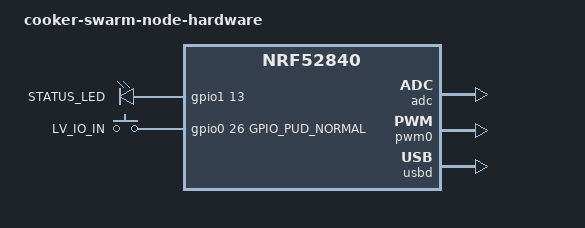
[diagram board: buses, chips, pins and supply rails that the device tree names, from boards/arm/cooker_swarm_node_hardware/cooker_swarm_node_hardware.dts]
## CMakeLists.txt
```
cmake_minimum_required(VERSION 3.8.2)

#set(BOARD_ROOT ${CMAKE_CURRENT_LIST_DIR})
#set(BOARD cooker_swarm_node_hardware)

include($ENV{ZEPHYR_BASE}/cmake/app/boilerplate.cmake NO_POLICY_SCOPE)
project(cooker-node)

target_sources(app PRIVATE
  src/main.c
  src/cooker.c
  src/cos.c
  src/cts.c
  src/ess.c
  src/remote_temp.c
  src/pid.c
)
```

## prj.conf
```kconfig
# POWER SAVING
#CONFIG_DEBUG=n
#CONFIG_SERIAL=n
#CONFIG_UART_NRFX=n
#CONFIG_SPEED_OPTIMIZATIONS=y
#CONFIG_BT_DEBUG_LOG=n

CONFIG_LOG=y
#CONFIG_LOG_BACKEND_UART=n

CONFIG_BT_MAX_CONN=2
CONFIG_BT_MAX_SCO_CONN=2

#CONFIG_CONSOLE=n
#CONFIG_UART_CONSOLE=n

# GENERAL
CONFIG_REBOOT=y

# DEVICES
CONFIG_ADC=y
CONFIG_GPIO=y
CONFIG_PWM=y

# BLUETOOTH
CONFIG_BT=y
CONFIG_BT_CENTRAL=y
CONFIG_BT_PERIPHERAL=y
CONFIG_BT_GATT_CLIENT=y
CONFIG_BT_DEVICE_NAME="cooker-swarm-node"
CONFIG_BT_CTLR_TX_PWR_PLUS_8=y

# POWER MANAGEMENT
CONFIG_SYS_POWER_MANAGEMENT=y
CONFIG_DEVICE_POWER_MANAGEMENT=y
```

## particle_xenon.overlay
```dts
/ {
	leds {
		compatible = "gpio-leds";
		led0: led_0 {
		  gpios = <&gpio1 13 0>;
		  label = "STATUS_LED";
	  	};
	};

	gpio_keys {
		compatible = "gpio-keys";
		lv_io_in: button_0 {
			gpios = <&gpio0 26 GPIO_PUD_NORMAL>;
			label = "LV_IO_IN";
		};
	};

	/* These aliases are provided for compatibility with samples */
	aliases {
		led0 = &led0;
	};
};

&pwm0 {
	status = "okay";
	ch0-pin = <45>;	// status LED
	ch0-inverted;
	ch1-pin = <8>;	// power out
	ch1-inverted;
};
```

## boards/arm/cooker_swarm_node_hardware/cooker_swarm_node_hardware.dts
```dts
/*
 * Copyright (c) 2020 Christian Hirsch
 *
 * SPDX-License-Identifier: Apache-2.0
 */

/dts-v1/;
#include <nordic/nrf52840_qiaa.dtsi>

/ {
	model = "cooker-swarm-node-hardware";
	compatible = "nordic,nrf52840-qiaa",
			   "nordic,nrf52840";

	chosen {
		zephyr,sram = &sram0;
		zephyr,flash = &flash0;
		zephyr,code-partition = &slot0_partition;
	};

	leds {
		compatible = "gpio-leds";
		led0: led_0 {
		  gpios = <&gpio1 13 0>;
		  label = "STATUS_LED";
	  	};
	};

	gpio_keys {
		compatible = "gpio-keys";
		lv_io_in: button_0 {
			gpios = <&gpio0 26 GPIO_PUD_NORMAL>;
			label = "LV_IO_IN";
		};
	};

	/* These aliases are provided for compatibility with samples */
	aliases {
		led0 = &led0;
	};
};

&adc {
	status = "okay";
};

&gpiote {
	status = "okay";
};

&gpio0 {
	status = "okay";
};

&gpio1 {
	status = "okay";
};

&pwm0 {
	status = "okay";
	ch0-pin = <45>;	// status LED
	ch0-inverted;
	ch1-pin = <8>;	// power out
	ch1-inverted;
};

&flash0 {
	/*
	 * For more information, see:
	 * http://docs.zephyrproject.org/latest/guides/dts/index.html#flash-partitions
	 */
	partitions {
		compatible = "fixed-partitions";
		#address-cells = <1>;
		#size-cells = <1>;

		boot_partition: partition@0 {
			label = "mcuboot";
			reg = <0x000000000 0x0000C000>;
		};
		slot0_partition: partition@c000 {
			label = "image-0";
			reg = <0x0000C000 0x000067000>;
		};
		slot1_partition: partition@73000 {
			label = "image-1";
			reg = <0x00073000 0x000067000>;
		};
		scratch_partition: partition@da000 {
			label = "image-scratch";
			reg = <0x000da000 0x0001e000>;
		};

		/*
		 * The flash starting at 0x000f8000 and ending at
		 * 0x000fffff is reserved for use by the application.
		 */

		/* Storage partition will be used by FCB/NFFS/NVS if enabled. */
		storage_partition: partition@f8000 {
			label = "storage";
			reg = <0x000f8000 0x00008000>;
		};
	};
};

&usbd {
	compatible = "nordic,nrf-usbd";
	status = "okay";
};
```

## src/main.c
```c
/*
 *
 */

#include <zephyr.h>
#include <zephyr/types.h>
#include <misc/byteorder.h>
#include <logging/log.h>
#include <settings/settings.h>
#include <device.h>
#include <gpio.h>
#include <soc.h>

#include <stddef.h>
#include <string.h>
#include <errno.h>

#include <bluetooth/bluetooth.h>
#include <bluetooth/hci.h>
#include <bluetooth/conn.h>
#include <bluetooth/uuid.h>
#include <bluetooth/gatt.h>

#include "cooker.h"
#include "remote_temp.h"
#include "cos.h"
#include "cts.h"

#include "config.h"

#include <drivers/pwm.h>


#ifndef IBEACON_RSSI
#define IBEACON_RSSI 0xc8
#endif

#define SENSE_INTERVAL 5
#define MEASUREMENTS_SIZE  10

/* in microseconds */
#define MIN_PERIOD	(USEC_PER_SEC / 64U)

/* in microseconds */
#define MAX_PERIOD	USEC_PER_SEC

// BT_GAP_ADV_SLOW_INT_MIN = 0x0640 ^= 1s
// BT_GAP_ADV_SLOW_INT_MAX = 0x0780 ^= 1.2s
#define BT_LE_ADV_CONN_NAME_ID BT_LE_ADV_PARAM(BT_LE_ADV_OPT_CONNECTABLE | \
                         BT_LE_ADV_OPT_USE_NAME | BT_LE_ADV_OPT_USE_IDENTITY, \
                         BT_GAP_ADV_SLOW_INT_MIN, \
                         BT_GAP_ADV_SLOW_INT_MAX)

LOG_MODULE_REGISTER(main);

void create_device_list(void);

struct {
	u32_t timestamp;
	u16_t battery;
} measurements[MEASUREMENTS_SIZE];

s16_t buf_start = 0;
s16_t buf_end   = 0;
u32_t sense_interval_mult = 1;

struct bt_le_adv_param *adv_params = BT_LE_ADV_CONN_NAME_ID;

static const struct bt_data ad[] = {
		BT_DATA_BYTES(BT_DATA_FLAGS, BT_LE_AD_NO_BREDR),
		BT_DATA_BYTES(BT_DATA_UUID16_ALL, 0xaa, 0xfe),
		BT_DATA_BYTES(BT_DATA_SVC_DATA16,
				0xaa, 0xfe,		/* Eddystone UUID */
				0x10,			/* Eddystone-URL frame type */
				0x04,			/* Calibrated Tx power at 0m */
				0x02,			/* URL Scheme Prefix http:// */
				'b','r','e','w','c','e','.',
				'c','h','r','i','v','i','e','h',
				0x03)
};

static void connected(struct bt_conn *conn, u8_t err)
{
	if (err) {
		LOG_INF("Connection failed (err %u)\n", err);
		return;
	}

	struct bt_conn_info info;
	if(bt_conn_get_info(conn, &info) != 0) {
		return;
	}
	if(info.role == BT_CONN_ROLE_MASTER) {
		LOG_INF("BT_CONN_ROLE_MASTER");
		return;
	}

	bt_le_adv_stop();
	LOG_INF("Connected with role %u", info.role);
}

static void disconnected(struct bt_conn *conn, u8_t reason)
{
	struct bt_conn_info info;
	if(bt_conn_get_info(conn, &info) != 0) {
		return;
	}
	if(info.role == BT_CONN_ROLE_MASTER) {
		return;
	}

	LOG_INF("Disconnected (reason %u)", reason);

	int err = 0;
	err = bt_le_adv_start(adv_params, ad, ARRAY_SIZE(ad), NULL, 0);
	if (err) {
		LOG_ERR("Advertising failed to start (err %d)", err);
		return;
	}
    LOG_INF("Advertising successfully started");
}

static struct bt_conn_cb conn_callbacks = {
	.connected = connected,
	.disconnected = disconnected,
};

static void bt_ready(int err)
{
	if (err) {
		return;
	}

	if (IS_ENABLED(CONFIG_SETTINGS)) {
		settings_load();
	}

	err = bt_le_adv_start(adv_params, ad, ARRAY_SIZE(ad), NULL, 0);
	if (err) {
		LOG_ERR("Advertising failed to start (err %d)", err);
		return;
	}
}

void main(void)
{
	LOG_INF("Application started");
	int err = 0;

	err = bt_enable(bt_ready);
	if (err) {
		LOG_ERR("Bluetooth init failed (err %d)", err);
		//return;
	}
    bt_conn_cb_register(&conn_callbacks);

    initilize_remote();
	cooker_init();

	while (1) {
		k_sleep(K_FOREVER);
	}
}
```

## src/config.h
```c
#if defined(DT_ALIAS_PWM_0_LABEL)
#define PWM_DRIVER	DT_ALIAS_PWM_0_LABEL

#if defined(DT_ALIAS_PWM_0_CH0_PIN)
#define STATUS_LED_CHANNEL	DT_ALIAS_PWM_0_CH0_PIN
#else
#error "Choose status LED PWM channel"
#endif

#if defined(DT_ALIAS_PWM_0_CH1_PIN)
#define POWER_OUT_CHANNEL	DT_ALIAS_PWM_0_CH1_PIN
#else
#error "Choose power out PWM channel"
#endif

#else
#error "Choose supported PWM driver"
#endif

#ifdef CONFIG_SOC_NRF52840_QIAA
#ifdef DT_ALIAS_ADC_0_LABEL
#include <hal/nrf_saadc.h>
#define ADC_DRIVER DT_ALIAS_ADC_0_LABEL
#define BATTERY_SENSE_PIN NRF_SAADC_INPUT_AIN2  // P0.04/AIN2
#else
#error "you need to define ADC 0"
#endif
#endif

#ifndef DT_GPIO_KEYS_BUTTON_0_GPIOS_CONTROLLER
#ifdef BUTTON0_GPIO_NAME
#define DT_ALIAS_SW0_GPIOS_CONTROLLER SW0_GPIO_NAME
#else
#error BUTTON0_GPIO_NAME or DT_GPIO_KEYS_BUTTON_0_GPIOS_CONTROLLER needs to be set in board.h
#endif
#endif
#define GPIO_DRIVER	DT_GPIO_KEYS_BUTTON_0_GPIOS_CONTROLLER

#ifdef DT_GPIO_KEYS_BUTTON_0_GPIOS_PIN
#define IO_INPUT_PIN     DT_GPIO_KEYS_BUTTON_0_GPIOS_PIN
#else
#error DT_GPIO_KEYS_BUTTON_0_GPIOS_CONTROLLER needs to be set in board.h
#endif

#ifdef DT_GPIO_KEYS_BUTTON_0_GPIOS_FLAGS
#define IO_INPUT_PIN_EDGE    (DT_GPIO_KEYS_BUTTON_0_GPIOS_FLAGS | GPIO_INT_EDGE | GPIO_INT_ACTIVE_HIGH)
#else
#error DT_GPIO_KEYS_BUTTON_0_GPIOS_FLAGS needs to be set in board.h
#endif

#ifdef DT_ALIAS_GPIO_0_LABEL
#define IO_OUTPUT_PORT	DT_ALIAS_GPIO_0_LABEL
#define IO_OUTPUT_PIN	6	// P0.06
#else
#error "Choose supported GPIO 0 driver"
#endif
```

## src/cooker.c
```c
#include "cooker.h"

#include <zephyr.h>
#include <kernel.h>
#include <logging/log.h>
#include <device.h>

#include <adc.h>
#include <drivers/gpio.h>
#include <drivers/pwm.h>

#include "config.h"
#include "cos.h"
#include "pid.h"
#include "remote_temp.h"

#define	PERIOD	1000000UL	// 1000000ns = 1 kHz

u8_t output_power_level = 0;
u8_t output_io_level = 0;

s16_t input_power_level = 0;

static struct pid_state control_loop_pid;

struct device *adc_dev;
struct device *gpio_dev;
struct device *pwm_dev;

K_SEM_DEFINE(manual_enter_sem, 1, 1);
K_SEM_DEFINE(is_in_on_loop, 1, 1);

K_MUTEX_DEFINE(cooker_control_mutex);

static struct gpio_callback gpio_cb;

#define STACK_SIZE 1024
#define PRIORITY 5

K_THREAD_STACK_DEFINE(manual_power_loop_stack, STACK_SIZE);
struct k_thread manual_power_loop_data;
k_tid_t manual_power_loop_tid;

K_THREAD_STACK_DEFINE(is_on_loop_stack, STACK_SIZE);
struct k_thread is_on_loop_data;
k_tid_t is_on_loop_tid;

K_THREAD_STACK_DEFINE(cooker_control_loop_stack, STACK_SIZE);
struct k_thread cooker_control_loop_data;
k_tid_t cooker_control_loop_tid;

static void cooker_control_loop(struct k_timer *timer);
K_TIMER_DEFINE(cooker_control_loop_timer, cooker_control_loop, NULL);

static const struct adc_channel_cfg adc_cfg = {
		.gain             = ADC_GAIN_1_6,
		.reference        = ADC_REF_VDD_1_4,
		.acquisition_time = ADC_ACQ_TIME(ADC_ACQ_TIME_MICROSECONDS, 40),
		.channel_id       = 0,
		.input_positive   = BATTERY_SENSE_PIN,
};

struct adc_sequence adc_sequence = {
		.buffer      = &input_power_level,
		.buffer_size = sizeof(input_power_level),
		.resolution  = 10,
};

void set_status_led_level(u8_t level);

LOG_MODULE_REGISTER(cooker);

void manual_power_loop()
{
	k_sleep(100);	// debounce

	if(k_mutex_lock(&cooker_control_mutex, K_FOREVER) != 0)
	{
		k_sem_give(&manual_enter_sem);
		return;
	}

	while(get_input_io_level()) {

		set_output_io_level(1);

		u8_t power = get_input_power_level();
		set_output_power_level(power);

		k_sleep(20);
	}
	set_output_io_level(0);

	k_mutex_unlock(&cooker_control_mutex);

	k_sem_give(&manual_enter_sem);
}

void is_on_loop()
{
	while (get_output_io_level())
	{
		set_status_led_level(0xff);
		k_sleep(10);
		set_status_led_level(0x00);
		k_sleep(200);
		set_status_led_level(0xff);
		k_sleep(10);
		set_status_led_level(0x00);
		k_sleep(1750);
	}

	k_sem_give(&is_in_on_loop);
}

void cooker_control_loop_worker()
{
	if(k_mutex_lock(&cooker_control_mutex, K_NO_WAIT) != 0) {
		cooker_stop_control_loop();
		return;
	}

	s32_t value  = (s32_t) remote_read_temp();
	if (value < -27315) {
		LOG_ERR("Error getting remote temperature");
		set_output_io_level(0);
		k_mutex_unlock(&cooker_control_mutex);
		return;
	}
	LOG_INF("Setpoint = %d ; value = %d", control_loop_pid.setpoint, value);
	s32_t output = pid_calc_control_effort(&control_loop_pid, value) / 100;
	const s32_t cutoff = (255 * 500) / 3500;

	LOG_INF("Set output level %i (int_error = %i)", (output * 3500) / 255,
			control_loop_pid.int_error);
	if (output < cutoff) {
		if (get_output_io_level() != 0) {
			set_output_io_level(0);
		}
		cooker_start_control_loop(K_SECONDS(2));
		k_mutex_unlock(&cooker_control_mutex);
		return;
	}

	if (get_output_io_level() != 1) {
		set_output_io_level(1);
	}
	output -= cutoff;
	output *= 255;
	output /= 255 - cutoff;
	set_output_power_level((u8_t)output);

	cooker_start_control_loop(K_SECONDS(2));
	k_mutex_unlock(&cooker_control_mutex);
}

void io_switched(struct device *gpiob, struct gpio_callback *cb,
		u32_t pins)
{
	if(k_sem_take(&manual_enter_sem, K_NO_WAIT) == 0)
	{
		k_thread_create(&manual_power_loop_data, manual_power_loop_stack,
				K_THREAD_STACK_SIZEOF(manual_power_loop_stack),
				manual_power_loop,
				NULL, NULL, NULL,
				PRIORITY + 1, 0, K_NO_WAIT);
	}
}

static void cooker_control_loop(struct k_timer *timer)
{
	k_thread_create(&cooker_control_loop_data, cooker_control_loop_stack,
			K_THREAD_STACK_SIZEOF(cooker_control_loop_stack),
			cooker_control_loop_worker,
			NULL, NULL, NULL,
			PRIORITY + 1, 0, K_NO_WAIT);
}

void cooker_init()
{
	k_sem_init(&manual_enter_sem, 1, 1);

	pid_initialize_state(&control_loop_pid);
	control_loop_pid.setpoint = 2750;
	control_loop_pid.p = 100;
	control_loop_pid.i =   1;
	control_loop_pid.int_error_max = 25500;
	control_loop_pid.output_max = 25500;
	control_loop_pid.output_min = 0;

	adc_dev = device_get_binding(ADC_DRIVER);
	if (!adc_dev) {
		LOG_ERR("Cannot find %s!\n", ADC_DRIVER);
		return;
	}

	gpio_dev = device_get_binding(GPIO_DRIVER);
	if(!gpio_dev) {
		LOG_ERR("Cannot find %s!\n", GPIO_DRIVER);
		return;
	}

	pwm_dev = device_get_binding(PWM_DRIVER);
	if (!pwm_dev) {
		LOG_ERR("Cannot find %s!\n", PWM_DRIVER);
		return;
	}

	adc_channel_setup(adc_dev, &adc_cfg);

	gpio_pin_configure(gpio_dev, IO_INPUT_PIN,
			GPIO_DIR_IN | GPIO_INT | GPIO_INT_DEBOUNCE | IO_INPUT_PIN_EDGE);

	gpio_init_callback(&gpio_cb, io_switched, BIT(IO_INPUT_PIN));

	gpio_add_callback(gpio_dev, &gpio_cb);
	gpio_pin_enable_callback(gpio_dev, IO_INPUT_PIN);

	gpio_pin_configure(gpio_dev, IO_OUTPUT_PIN, GPIO_DIR_OUT);
	gpio_pin_write(gpio_dev, IO_OUTPUT_PIN, 0);
}

void cooker_start_control_loop(s32_t duration) {
	k_timer_start(&cooker_control_loop_timer, duration, 0);
}

void cooker_stop_control_loop(void) {
	k_timer_stop(&cooker_control_loop_timer);
}

/* 0xa8 (min) to 0x00 (max) */
u8_t get_input_power_level()
{
	int ret = 0;

	if(adc_channel_setup(adc_dev, &adc_cfg) != 0)
		return 255;

	adc_sequence.channels = BIT(adc_cfg.channel_id);
	ret = adc_read(adc_dev, &adc_sequence);

	if(ret < 0)
		return 255;

	input_power_level = (input_power_level >> 2) & 0x00ff;
	if (input_power_level > 0xf0UL)
		input_power_level = 0;
	input_power_level *= 0xffUL;
	input_power_level /= 0xaaUL;
	input_power_level  = 255 - input_power_level;

	cos_input_power_notify((u8_t) input_power_level);
	return (u8_t) input_power_level;
}

/*
 * VDD = low power
 * GND = full power
 */
void set_output_power_level(u8_t level)
{
	LOG_INF("Set output power level to %u", level);
	return;
	output_power_level = level;

	if (get_output_io_level() == 0)
		output_power_level = 0;

	cos_output_power_notify(output_power_level);

	u32_t period = (u32_t) output_power_level * PERIOD / 255UL;

	if (pwm_pin_set_nsec(pwm_dev, POWER_OUT_CHANNEL,
			PERIOD, period)) {
		LOG_ERR("pwm pin set fails\n");
		return;
	}
}

u8_t get_output_power_level()
{
	return output_power_level;
}

u8_t get_input_io_level()
{
	u32_t value;
	gpio_pin_read(gpio_dev, IO_INPUT_PIN, &value);
	cos_input_io_notify((u8_t) (value > 0));
	return (u8_t) (value > 0) ;
}

void set_output_io_level(u8_t level)
{
	LOG_INF("Set output io level to %u", level);
	return;
	output_io_level = level;
	cos_output_io_notify(output_io_level);
	if(output_io_level)
	{
		gpio_pin_write(gpio_dev, IO_OUTPUT_PIN, 1);

		if(k_sem_take(&is_in_on_loop, K_NO_WAIT) == 0)
		{
			k_thread_create(&is_on_loop_data, is_on_loop_stack,
					K_THREAD_STACK_SIZEOF(is_on_loop_stack),
					is_on_loop,
					NULL, NULL, NULL,
					7, 0, K_NO_WAIT);
		}
	}
	else
	{
		set_output_power_level(0);
		gpio_pin_write(gpio_dev, IO_OUTPUT_PIN, 0);
	}
}

u8_t get_output_io_level()
{
	return output_io_level;
}

void set_status_led_level(u8_t level)
{
	u32_t period = (u32_t) level * PERIOD / 255UL;

	if (pwm_pin_set_nsec(pwm_dev, STATUS_LED_CHANNEL,
			PERIOD, period)) {
		LOG_ERR("pwm pin set fails\n");
	}
}

void cooker_set_control_setpoint(s32_t setpoint)
{
	control_loop_pid.setpoint = setpoint;
}

void cooker_set_control_pid_p_value(s32_t p)
{
	control_loop_pid.p = p;
}

void cooker_set_control_pid_i_value(s32_t i)
{
	control_loop_pid.i = i;
}

void cooker_set_control_pid_d_value(s32_t d)
{
	control_loop_pid.d = d;
}
```

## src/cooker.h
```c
#include <zephyr/types.h>

#ifdef __cplusplus
extern "C" {
#endif

void cooker_init();

u8_t get_input_power_level();

void set_output_power_level(u8_t level);
u8_t get_output_power_level();

u8_t get_input_io_level();

void set_output_io_level(u8_t level);
u8_t get_output_io_level();

void cooker_start_control_loop(s32_t duration);
void cooker_stop_control_loop(void);

void cooker_set_control_setpoint(s32_t setpoint);
void cooker_set_control_pid_p_value(s32_t p);
void cooker_set_control_pid_i_value(s32_t i);
void cooker_set_control_pid_d_value(s32_t d);

#ifdef __cplusplus
}
#endif
```

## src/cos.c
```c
#include <zephyr.h>
#include <kernel.h>
#include <zephyr/types.h>
#include <stddef.h>
#include <string.h>
#include <errno.h>
#include <misc/byteorder.h>

#include <bluetooth/bluetooth.h>
#include <bluetooth/addr.h>
#include <bluetooth/hci.h>
#include <bluetooth/conn.h>
#include <bluetooth/uuid.h>
#include <bluetooth/gatt.h>

#include "cooker.h"
#include "remote_temp.h"
#include "uuid.h"

#include "cos.h"

u8_t input_io_notify_enabled = 0;
u8_t input_power_notify_enabled = 0;

u8_t output_io_notify_enabled = 0;
u8_t output_power_notify_enabled = 0;

bt_addr_le_t remote_temp_device;
u16_t remote_temp_handle;

extern struct k_mutex cooker_control_mutex;

static void cos_set_input_io_ccc_cfg(const struct bt_gatt_attr *attr,
				 u16_t value);
static ssize_t cos_get_input_io_level(struct bt_conn *conn, const struct bt_gatt_attr *attr,
			 void *buf, u16_t len, u16_t offset);

static void cos_set_input_power_ccc_cfg(const struct bt_gatt_attr *attr,
				 u16_t value);
static ssize_t cos_get_input_power_level(struct bt_conn *conn, const struct bt_gatt_attr *attr,
			 void *buf, u16_t len, u16_t offset);

static void cos_set_output_io_ccc_cfg(const struct bt_gatt_attr *attr,
				 u16_t value);
static ssize_t cos_set_output_io_level(struct bt_conn *conn, const struct bt_gatt_attr *attr,
                        const void *buf, u16_t len, u16_t offset,
                        u8_t flags);

static void cos_set_output_power_ccc_cfg(const struct bt_gatt_attr *attr,
				 u16_t value);
static ssize_t cos_set_output_power_level(struct bt_conn *conn, const struct bt_gatt_attr *attr,
                        const void *buf, u16_t len, u16_t offset,
                        u8_t flags);

static ssize_t cos_set_remote_temp_probe(struct bt_conn *conn, const struct bt_gatt_attr *attr,
                        const void *buf, u16_t len, u16_t offset,
                        u8_t flags);

static ssize_t cos_set_control_state(struct bt_conn *conn, const struct bt_gatt_attr *attr,
                        const void *buf, u16_t len, u16_t offset,
                        u8_t flags);

static ssize_t cos_set_control_setpoint(struct bt_conn *conn, const struct bt_gatt_attr *attr,
                        const void *buf, u16_t len, u16_t offset,
                        u8_t flags);

static ssize_t cos_set_control_pid(struct bt_conn *conn, const struct bt_gatt_attr *attr,
                        const void *buf, u16_t len, u16_t offset,
                        u8_t flags);

/* Battery Service Declaration */
BT_GATT_SERVICE_DEFINE(cooker_service_cvs,
	BT_GATT_PRIMARY_SERVICE(BT_UUID_COS),

	BT_GATT_CHARACTERISTIC(BT_UUID_COS_INPUT_IO,
			       BT_GATT_CHRC_READ | BT_GATT_CHRC_NOTIFY,
			       BT_GATT_PERM_READ, cos_get_input_io_level, NULL, NULL),
	BT_GATT_CCC(cos_set_input_io_ccc_cfg, BT_GATT_PERM_READ | BT_GATT_PERM_WRITE),
	
	BT_GATT_CHARACTERISTIC(BT_UUID_COS_INPUT_POWER,
			       BT_GATT_CHRC_READ | BT_GATT_CHRC_NOTIFY,
			       BT_GATT_PERM_READ, cos_get_input_power_level, NULL, NULL),
	BT_GATT_CCC(cos_set_input_power_ccc_cfg, BT_GATT_PERM_READ | BT_GATT_PERM_WRITE),
	
	BT_GATT_CHARACTERISTIC(BT_UUID_COS_OUTPUT_IO,
			       BT_GATT_CHRC_WRITE | BT_GATT_CHRC_NOTIFY,
			       BT_GATT_PERM_WRITE, NULL, cos_set_output_io_level, NULL),
	BT_GATT_CCC(cos_set_output_io_ccc_cfg, BT_GATT_PERM_READ | BT_GATT_PERM_WRITE),
	
	BT_GATT_CHARACTERISTIC(BT_UUID_COS_OUTPUT_POWER,
			       BT_GATT_CHRC_WRITE | BT_GATT_CHRC_NOTIFY,
			       BT_GATT_PERM_WRITE, NULL, cos_set_output_power_level, NULL),
	BT_GATT_CCC(cos_set_output_power_ccc_cfg, BT_GATT_PERM_READ | BT_GATT_PERM_WRITE),

	BT_GATT_CHARACTERISTIC(BT_UUID_COS_REMOTE_TEMP_PROBE,
				BT_GATT_CHRC_WRITE,
				BT_GATT_PERM_WRITE, NULL, cos_set_remote_temp_probe, NULL),
	BT_GATT_CCC(NULL, BT_GATT_PERM_NONE),

	BT_GATT_CHARACTERISTIC(BT_UUID_COS_CONTROL_STATE,
				BT_GATT_CHRC_WRITE,
				BT_GATT_PERM_WRITE, NULL, cos_set_control_state, NULL),
	BT_GATT_CCC(NULL, BT_GATT_PERM_NONE),

	BT_GATT_CHARACTERISTIC(BT_UUID_COS_CONTROL_SETPOINT,
			BT_GATT_CHRC_WRITE,
			BT_GATT_PERM_WRITE, NULL, cos_set_control_setpoint, NULL),
	BT_GATT_CCC(NULL, BT_GATT_PERM_NONE),

	BT_GATT_CHARACTERISTIC(BT_UUID_COS_CONTROL_PID,
			BT_GATT_CHRC_WRITE,
			BT_GATT_PERM_WRITE, NULL, cos_set_control_pid, NULL),
	BT_GATT_CCC(NULL, BT_GATT_PERM_NONE),
);

static void cos_set_input_io_ccc_cfg(const struct bt_gatt_attr *attr,
				 u16_t value)
{
	input_io_notify_enabled = (value == BT_GATT_CCC_NOTIFY) ? 1 : 0;
}

static ssize_t cos_get_input_io_level(struct bt_conn *conn, const struct bt_gatt_attr *attr,
			 void *buf, u16_t len, u16_t offset)
{
	u8_t value;
	int err = bt_gatt_attr_read(conn, attr, buf, len, offset, &value,
				 sizeof(u8_t));

	return err;
}

static void cos_set_input_power_ccc_cfg(const struct bt_gatt_attr *attr,
				 u16_t value)
{
	input_power_notify_enabled = (value == BT_GATT_CCC_NOTIFY) ? 1 : 0;
}

static ssize_t cos_get_input_power_level(struct bt_conn *conn, const struct bt_gatt_attr *attr,
			 void *buf, u16_t len, u16_t offset)
{
	u8_t value = get_input_power_level();
	int err = bt_gatt_attr_read(conn, attr, buf, len, offset, &value,
				 sizeof(u8_t));

	return err;
}

static void cos_set_output_io_ccc_cfg(const struct bt_gatt_attr *attr,
				 u16_t value)
{
	output_io_notify_enabled = (value == BT_GATT_CCC_NOTIFY) ? 1 : 0;
}

static ssize_t cos_set_output_io_level(struct bt_conn *conn, const struct bt_gatt_attr *attr,
                        const void *buf, u16_t len, u16_t offset,
                        u8_t flags)
{
        u8_t value;

        if (offset + len > sizeof(value)) {
                return BT_GATT_ERR(BT_ATT_ERR_INVALID_OFFSET);
        }

        memcpy((&value) + offset, buf, len);

        if (k_mutex_lock(&cooker_control_mutex, K_NO_WAIT) == 0)
        {
        	value = (value == 1);
        	set_output_io_level(value);
        	k_mutex_unlock(&cooker_control_mutex);
        }

        return len;
}

static void cos_set_output_power_ccc_cfg(const struct bt_gatt_attr *attr,
				 u16_t value)
{
	output_power_notify_enabled = (value == BT_GATT_CCC_NOTIFY) ? 1 : 0;
}

static ssize_t cos_set_output_power_level(struct bt_conn *conn, const struct bt_gatt_attr *attr,
                        const void *buf, u16_t len, u16_t offset,
                        u8_t flags)
{
        u8_t value;

        if (offset + len > sizeof(value)) {
                return BT_GATT_ERR(BT_ATT_ERR_INVALID_OFFSET);
        }

        memcpy((&value) + offset, buf, len);

        if (k_mutex_lock(&cooker_control_mutex, K_NO_WAIT) == 0)
        {
        	set_output_power_level(value);

        	k_mutex_unlock(&cooker_control_mutex);
        }

        return len;
}

static ssize_t cos_set_remote_temp_probe(struct bt_conn *conn, const struct bt_gatt_attr *attr,
		const void *buf, u16_t len, u16_t offset,
		u8_t flags)
{
	static u8_t value[9] = { 0 };

	if (offset + len >
		(sizeof(remote_temp_device.type)
				+ sizeof(remote_temp_device.a)
				+ sizeof(remote_temp_handle) )) {
		return BT_GATT_ERR(BT_ATT_ERR_INVALID_OFFSET);
	}

	memcpy((&value) + offset, buf, len);

	memcpy(&(remote_temp_device.type), &(value[0]), sizeof(remote_temp_device.type));
	memcpy(&(remote_temp_device.a.val), &(value[1]), sizeof(remote_temp_device.a.val));
	memcpy(&remote_temp_handle, &(value[7]), sizeof(remote_temp_handle));

	remote_set_addr(&remote_temp_device);
	remote_set_handle(remote_temp_handle);

	return len;
}

static ssize_t cos_set_control_state(struct bt_conn *conn, const struct bt_gatt_attr *attr,
                        const void *buf, u16_t len, u16_t offset,
                        u8_t flags)
{
	u8_t state;
	if ((offset + len) > sizeof(state)) {
		return BT_GATT_ERR(BT_ATT_ERR_INVALID_OFFSET);
	}

	memcpy((&state) + offset, buf, len);

	if (state == 1) {
		cooker_start_control_loop(K_NO_WAIT);
	} else {
		cooker_stop_control_loop();
	}

	return len;
}

static ssize_t cos_set_control_setpoint(struct bt_conn *conn, const struct bt_gatt_attr *attr,
                        const void *buf, u16_t len, u16_t offset,
                        u8_t flags)
{
	s32_t setpoint;
	if ((offset + len) > sizeof(setpoint)) {
		return BT_GATT_ERR(BT_ATT_ERR_INVALID_OFFSET);
	}

	memcpy((&setpoint) + offset, buf, len);

	cooker_set_control_setpoint(setpoint);

	return len;
}

static ssize_t cos_set_control_pid(struct bt_conn *conn, const struct bt_gatt_attr *attr,
                        const void *buf, u16_t len, u16_t offset,
                        u8_t flags)
{
	s32_t values[10];

	if ((offset + len) > sizeof(values)) {
		return BT_GATT_ERR(BT_ATT_ERR_INVALID_OFFSET);
	}

	memcpy((&values) + offset, buf, len);

	cooker_set_control_pid_p_value(values[0]);
	cooker_set_control_pid_p_value(values[1]);
	cooker_set_control_pid_p_value(values[2]);

	return len;
}

int cos_input_io_notify(u8_t value)
{
	if (!input_io_notify_enabled) {
		return 0;
	}

	return bt_gatt_notify(NULL, &cooker_service_cvs.attrs[1], &value, sizeof(u8_t));
}

int cos_input_power_notify(u8_t value)
{
	if (!input_power_notify_enabled) {
		return 0;
	}

	return bt_gatt_notify(NULL, &cooker_service_cvs.attrs[3], &value, sizeof(u8_t));
}

int cos_output_io_notify(u8_t value)
{
	if (!output_io_notify_enabled) {
		return 0;
	}

	return bt_gatt_notify(NULL, &cooker_service_cvs.attrs[5], &value, sizeof(u8_t));
}

int cos_output_power_notify(u8_t value)
{
	if (!output_power_notify_enabled) {
		return 0;
	}

	return bt_gatt_notify(NULL, &cooker_service_cvs.attrs[7], &value, sizeof(u8_t));
}
```

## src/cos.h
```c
#ifdef __cplusplus
extern "C" {
#endif

void cos_init(void);

int cos_input_io_notify(u8_t value);
int cos_input_power_notify(u8_t value);
int cos_output_io_notify(u8_t value);
int cos_output_power_notify(u8_t value);

#ifdef __cplusplus
}
#endif
```

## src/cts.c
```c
#include <zephyr/types.h>
#include <stddef.h>
#include <string.h>
#include <errno.h>
#include <misc/byteorder.h>
#include <zephyr.h>

#include <bluetooth/bluetooth.h>
#include <bluetooth/hci.h>
#include <bluetooth/conn.h>
#include <bluetooth/uuid.h>
#include <bluetooth/gatt.h>

#include "cts.h"

extern u16_t buf_start;
extern u16_t buf_end;

u8_t   cts_notify_enabled = 0;
u8_t   cts_time_synced = 0;
static u32_t time;

static void cts_ccc_cfg_changed(const struct bt_gatt_attr *attr,
				 u16_t value)
{
	cts_notify_enabled = (value == BT_GATT_CCC_NOTIFY) ? 1 : 0;

}

static ssize_t read_cts(struct bt_conn *conn, const struct bt_gatt_attr *attr,
			 void *buf, u16_t len, u16_t offset)
{
	time = k_uptime_get_32();

	if(buf_start == buf_end)
		time = 0;

	int err = bt_gatt_attr_read(conn, attr, buf, len, offset, &time,
				 sizeof(u32_t));

	cts_time_synced = 1;

	return err;
}

/* Battery Service Declaration */
BT_GATT_SERVICE_DEFINE(cts_svc,
	BT_GATT_PRIMARY_SERVICE(BT_UUID_CTS),
	BT_GATT_CHARACTERISTIC(BT_UUID_CTS_CURRENT_TIME,
			       BT_GATT_CHRC_READ | BT_GATT_CHRC_NOTIFY,
			       BT_GATT_PERM_READ, read_cts, NULL, &time),
	BT_GATT_CCC(cts_ccc_cfg_changed, BT_GATT_PERM_READ | BT_GATT_PERM_WRITE),
);

int cts_notify(u32_t _timestamp)
{
	if (!cts_notify_enabled) {
		return 0;
	}

	return bt_gatt_notify(NULL, &cts_svc.attrs[1], &_timestamp, sizeof(u32_t));
}
```

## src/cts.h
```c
#ifdef __cplusplus
extern "C" {
#endif

void cts_init(void);
int  cts_notify(u32_t _timestamp);

#ifdef __cplusplus
}
#endif
```

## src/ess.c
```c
#include <zephyr.h>
#include <stddef.h>

#include <bluetooth/uuid.h>
#include <bluetooth/gatt.h>

#include <drivers/sensor.h>

#include <logging/log.h>

#include "remote_temp.h"

static u8_t enable_temp_notifications;

LOG_MODULE_REGISTER(ess);

static void ess_temp_ccc_cfg_changed(const struct bt_gatt_attr *attr,
				 u16_t value);
static ssize_t read_remote_temp(struct bt_conn *conn, const struct bt_gatt_attr *attr,
        void *buf, u16_t len, u16_t offset);

/* ESS Declaration */
BT_GATT_SERVICE_DEFINE(ess_svc,
	BT_GATT_PRIMARY_SERVICE(BT_UUID_ESS),
	BT_GATT_CHARACTERISTIC(BT_UUID_TEMPERATURE,
			       BT_GATT_CHRC_READ | BT_GATT_CHRC_NOTIFY,
				   BT_GATT_PERM_READ, NULL, NULL, NULL),
	BT_GATT_CCC(ess_temp_ccc_cfg_changed, BT_GATT_PERM_WRITE),
);

static void ess_temp_ccc_cfg_changed(const struct bt_gatt_attr *attr,
				 u16_t value)
{
	enable_temp_notifications = (value == BT_GATT_CCC_NOTIFY) ? 1 : 0;
}

static ssize_t read_remote_temp(struct bt_conn *conn, const struct bt_gatt_attr *attr,
        void *buf, u16_t len, u16_t offset)
{
	/*
	s16_t *temp_buf;
	s16_t temperature = -25000;

	u16_t ret = remote_read_handle(&temp_buf);
	if (ret == 0) {
		return bt_gatt_attr_read(conn, attr, buf, len, offset, &temperature,
		            sizeof(temperature));
	}

	temperature = 666;

    return bt_gatt_attr_read(conn, attr, buf, len, offset, &temperature,
            sizeof(temperature));
            */
	return 0;
}

int ess_temp_notify(s16_t temp)
{
	LOG_INF("Notify with %d", temp);
	if (!enable_temp_notifications) {
		return 0;
	}

	return bt_gatt_notify(NULL, &ess_svc.attrs[1],
			&temp, sizeof(temp));
}
```

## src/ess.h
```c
#ifdef __cplusplus
extern "C" {
#endif

int ess_temp_notify(s16_t temp);

#ifdef __cplusplus
}
#endif
```

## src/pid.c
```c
#include "pid.h"

#include <kernel.h>

void pid_initialize_state(struct pid_state *state)
{
	state->setpoint = 0;
	state->p = 0;
	state->i = 0;
	state->d = 0;
	state->int_error = 0;
	state->int_error_max = 0;
	state->int_error_min = 0;
	state->pre_error = 0;
	state->timestamp = k_uptime_get_32();
	state->output_max = 100;
	state->output_min = 0;
}

s32_t pid_calc_control_effort(struct pid_state *state, s32_t value)
{
	u32_t timestamp = k_uptime_get_32();
	s32_t dt = timestamp - state->timestamp;
	state->timestamp = timestamp;

	s32_t error = state->setpoint - value;

    s32_t deriv_error = error - state->pre_error;
    state->pre_error  = error;
    state->int_error += (error * dt) / 1000;

    if (state->int_error > state->int_error_max) {
		state->int_error = state->int_error_max;
    } else if (state->int_error < state->int_error_min) {
    	state->int_error = state->int_error_min;
    }

    s32_t output;
    output  = state->p * error;
    output += state->i * state->int_error;
    output += (state->d * deriv_error * 1000) / dt;

    if (output > state->output_max) {
    	return state->output_max;
    } else if (output < state->output_min) {
    	return state->output_min;
    }

    return output;
}
```

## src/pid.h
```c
#ifndef PID_H_
#define PID_H_

#ifdef __cplusplus
extern "C" {
#endif

#include <zephyr/types.h>

struct pid_state {
	s32_t p, i, d;
	s32_t int_error, int_error_max, int_error_min;
	s32_t pre_error;

	s32_t setpoint;
	u32_t timestamp;
	s32_t output_max, output_min;
};

void pid_initialize_state(struct pid_state *state);
s32_t pid_calc_control_effort(struct pid_state *state, s32_t value);

#ifdef __cplusplus
}
#endif

#endif /* PID_H_ */
```

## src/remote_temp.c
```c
#include <zephyr.h>
#include <bluetooth/bluetooth.h>
#include <bluetooth/hci.h>
#include <bluetooth/conn.h>
#include <bluetooth/gatt.h>

#include <logging/log.h>

#include "ess.h"

static bt_addr_le_t *remote_addr = NULL;
static struct bt_conn *remote_conn = NULL;
static struct bt_gatt_read_params read_params;

static void connected(struct bt_conn *conn, u8_t err);
static void disconnected(struct bt_conn *conn, u8_t reason);
static u8_t remote_read_cb(struct bt_conn *conn, u8_t err,
		struct bt_gatt_read_params *params,
		const void *data, u16_t length);
static void disconnect_timeout(struct k_timer *timer);

static struct {
	u8_t  buf[10];
	u16_t length;
} remote_data;

K_THREAD_STACK_DEFINE(remote_read_stack_area, 1024);
struct k_thread remote_read_data;
k_tid_t remote_read_tid;

static void remote_read_worker(void *, void *, void *);

K_SEM_DEFINE(read_remote_handle_mutex, 0, 1);
K_SEM_DEFINE(connect_remote_device, 0, 1);
K_TIMER_DEFINE(disconnect_timer, disconnect_timeout, NULL);

LOG_MODULE_REGISTER(remote_temp);

static struct bt_conn_cb conn_callbacks = {
		.connected = connected,
		.disconnected = disconnected,
};

void initilize_remote(void)
{
	bt_conn_cb_register(&conn_callbacks);

	read_params.func = remote_read_cb;
}

void remote_set_addr(bt_addr_le_t *addr)
{
	remote_addr = addr;
}

void remote_set_handle(u16_t handle)
{
	read_params.handle_count = 1;
	read_params.single.handle = handle;
	read_params.single.offset = 0;
}

static int remote_connect(void)
{
	if (remote_addr == NULL)
		return -1;

	char addr[BT_ADDR_LE_STR_LEN];

	bt_addr_le_to_str(remote_addr, addr, sizeof(addr));

	LOG_INF("Connect to remote device %s", addr);
	remote_conn = bt_conn_create_le(remote_addr, BT_LE_CONN_PARAM_DEFAULT);

	return 0;
}

static void remote_disconnect(void)
{
	bt_conn_disconnect(remote_conn, BT_HCI_ERR_REMOTE_USER_TERM_CONN);
}

static void connected(struct bt_conn *conn, u8_t err)
{
	if (err) {
		LOG_INF("Connection failed (err %u)", err);
		return;
	}

	if (remote_conn != conn) {
		return;
	}
	LOG_INF("Conncted to remote device");

	k_sem_give(&connect_remote_device);
	k_timer_start(&disconnect_timer, K_MINUTES(5), 0);
}

static void disconnected(struct bt_conn *conn, u8_t reason)
{
	if (remote_conn != conn) {
		return;
	}

	remote_conn = NULL;
	k_timer_stop(&disconnect_timer);
}

static u8_t remote_read_cb(struct bt_conn *conn, u8_t err,
		struct bt_gatt_read_params *params,
		const void *data, u16_t length)
{
	LOG_INF("Received remote data");

	remote_data.length = length;
	memcpy(remote_data.buf, data, length);
	if (k_sem_take(&read_remote_handle_mutex, K_NO_WAIT) != 0) {
		k_sem_give(&read_remote_handle_mutex);
	}

	ess_temp_notify(*(s16_t *)remote_data.buf);

	return 0;
}

u16_t remote_read_handle(void **buf)
{
	remote_read_tid = k_thread_create(&remote_read_data, remote_read_stack_area,
			K_THREAD_STACK_SIZEOF(remote_read_stack_area),
			remote_read_worker,
			NULL, NULL, NULL,
			5, 0, K_NO_WAIT);
	return 0;
}

static void disconnect_timeout(struct k_timer *timer)
{
	remote_disconnect();
}

static void remote_read_worker(void *b1, void *b2, void *b3)
{
	if (remote_conn == NULL) {
		if (remote_connect() != 0) {
			LOG_ERR("Error connecting to remote device");
			return;
		}
		LOG_INF("Waiting for connection");
		if(k_sem_take(&connect_remote_device, K_SECONDS(30)) != 0) {
			LOG_ERR("Connect to remote device timed out");
			return;
		}
		k_sem_give(&connect_remote_device);
	}
	k_timer_start(&disconnect_timer, K_MINUTES(5), 0);

	LOG_INF("Reading remote handle");

	bt_gatt_read(remote_conn, &read_params);
}

s16_t remote_read_temp(void)
{
	remote_read_tid = k_thread_create(&remote_read_data, remote_read_stack_area,
			K_THREAD_STACK_SIZEOF(remote_read_stack_area),
			remote_read_worker,
			NULL, NULL, NULL,
			5, 0, K_NO_WAIT);

	if (k_sem_take(&read_remote_handle_mutex, K_SECONDS(10)) != 0) {
		LOG_ERR("Read remote handle timed out");
		return -32767;
	}

	return *(s16_t *)remote_data.buf;
}
```
